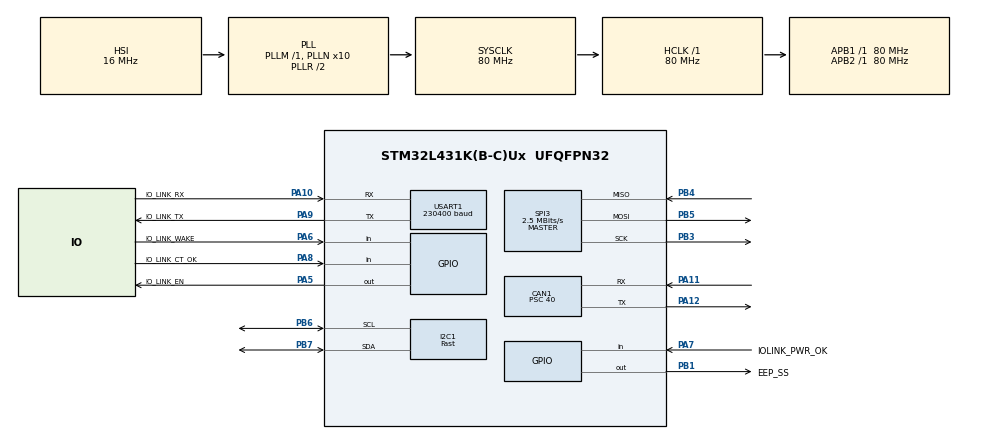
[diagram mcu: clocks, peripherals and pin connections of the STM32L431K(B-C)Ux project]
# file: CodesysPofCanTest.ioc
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CAN1.BS1=CAN_BS1_13TQ
CAN1.BS2=CAN_BS2_2TQ
CAN1.CalculateTimeQuantum=500.0
CAN1.Prescaler=40
CAN1.SJW=CAN_SJW_1TQ
I2C1.I2C_Speed_Mode=I2C_Fast
I2C1.Timing=0x00702991
Mcu.Family=STM32L4
Mcu.Name=STM32L431K(B-C)Ux
Mcu.Package=UFQFPN32
NVIC.CAN1_RX0_IRQn=true\:1\:0\:true\:false\:true\:true
NVIC.CAN1_RX1_IRQn=true\:1\:0\:true\:false\:true\:true
NVIC.CAN1_TX_IRQn=true\:1\:0\:true\:false\:true\:true
NVIC.PriorityGroup=NVIC_PRIORITYGROUP_4
NVIC.SPI3_IRQn=true\:0\:0\:false\:false\:true\:true
NVIC.USART1_IRQn=true\:0\:0\:false\:false\:true\:true
PA10.GPIO_Label=IO_LINK_RX
PA10.Mode=Asynchronous
PA10.Signal=USART1_RX
PA11.Mode=Master
PA11.Signal=CAN1_RX
PA12.Mode=Master
PA12.Signal=CAN1_TX
PA5.GPIO_Label=IO_LINK_EN
PA5.Signal=GPIO_Output
PA6.GPIO_Label=IO_LINK_WAKE
PA6.Signal=GPIO_Input
PA7.GPIO_Label=IOLINK_PWR_OK
PA7.Signal=GPIO_Input
PA8.GPIO_Label=IO_LINK_CT_OK
PA8.Signal=GPIO_Input
PA9.GPIO_Label=IO_LINK_TX
PA9.Mode=Asynchronous
PA9.Signal=USART1_TX
PB1.GPIO_Label=EEP_SS
PB1.Signal=GPIO_Output
PB3\ (JTDO-TRACESWO).Mode=Full_Duplex_Master
PB3\ (JTDO-TRACESWO).Signal=SPI3_SCK
PB4\ (NJTRST).Mode=Full_Duplex_Master
PB4\ (NJTRST).Signal=SPI3_MISO
PB5.Mode=Full_Duplex_Master
PB5.Signal=SPI3_MOSI
PB6.Mode=I2C
PB6.Signal=I2C1_SCL
PB7.Mode=I2C
PB7.Signal=I2C1_SDA
ProjectManager.HeapSize=0x200
ProjectManager.StackSize=0x400
ProjectManager.TargetToolchain=TrueSTUDIO
RCC.ADCFreq_Value=64000000
RCC.AHBFreq_Value=80000000
RCC.APB1Freq_Value=80000000
RCC.APB1TimFreq_Value=80000000
RCC.APB2Freq_Value=80000000
RCC.APB2TimFreq_Value=80000000
RCC.CortexFreq_Value=80000000
RCC.HCLKFreq_Value=80000000
RCC.HSE_VALUE=8000000
RCC.HSI48_VALUE=48000000
RCC.HSI_VALUE=16000000
RCC.LSE_VALUE=32768
RCC.MSI_VALUE=4000000
RCC.PLLN=10
RCC.PLLSourceVirtual=RCC_PLLSOURCE_HSI
RCC.SYSCLKFreq_VALUE=80000000
RCC.SYSCLKSource=RCC_SYSCLKSOURCE_PLLCLK
RCC.VCOOutputFreq_Value=160000000
SPI3.BaudRatePrescaler=SPI_BAUDRATEPRESCALER_32
SPI3.CalculateBaudRate=2.5 MBits/s
SPI3.DataSize=SPI_DATASIZE_8BIT
SPI3.Direction=SPI_DIRECTION_2LINES
SPI3.Mode=SPI_MODE_MASTER
SPI3.VirtualType=VM_MASTER
TIM6.Period=249
TIM6.Prescaler=319
USART1.BaudRate=230400
USART1.Parity=PARITY_EVEN
USART1.VirtualMode-Asynchronous=VM_ASYNC
USART1.WordLength=WORDLENGTH_9B
VP_TIM6_VS_ClockSourceINT.Mode=Enable_Timer
board=CodesysPofCanTest

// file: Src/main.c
/**
  ******************************************************************************
  * @file           : main.c
  * @brief          : Main program body
  ******************************************************************************
  ** This notice applies to any and all portions of this file
  * that are not between comment pairs USER CODE BEGIN and
  * USER CODE END. Other portions of this file, whether
  * inserted by the user or by software development tools
  * are owned by their respective copyright owners.
  *
  * COPYRIGHT(c) 2018 STMicroelectronics
  *
  * Redistribution and use in source and binary forms, with or without modification,
  * are permitted provided that the following conditions are met:
  *   1. Redistributions of source code must retain the above copyright notice,
  *      this list of conditions and the following disclaimer.
  *   2. Redistributions in binary form must reproduce the above copyright notice,
  *      this list of conditions and the following disclaimer in the documentation
  *      and/or other materials provided with the distribution.
  *   3. Neither the name of STMicroelectronics nor the names of its contributors
  *      may be used to endorse or promote products derived from this software
  *      without specific prior written permission.
  *
  * THIS SOFTWARE IS PROVIDED BY THE COPYRIGHT HOLDERS AND CONTRIBUTORS "AS IS"
  * AND ANY EXPRESS OR IMPLIED WARRANTIES, INCLUDING, BUT NOT LIMITED TO, THE
  * IMPLIED WARRANTIES OF MERCHANTABILITY AND FITNESS FOR A PARTICULAR PURPOSE ARE
  * DISCLAIMED. IN NO EVENT SHALL THE COPYRIGHT HOLDER OR CONTRIBUTORS BE LIABLE
  * FOR ANY DIRECT, INDIRECT, INCIDENTAL, SPECIAL, EXEMPLARY, OR CONSEQUENTIAL
  * DAMAGES (INCLUDING, BUT NOT LIMITED TO, PROCUREMENT OF SUBSTITUTE GOODS OR
  * SERVICES; LOSS OF USE, DATA, OR PROFITS; OR BUSINESS INTERRUPTION) HOWEVER
  * CAUSED AND ON ANY THEORY OF LIABILITY, WHETHER IN CONTRACT, STRICT LIABILITY,
  * OR TORT (INCLUDING NEGLIGENCE OR OTHERWISE) ARISING IN ANY WAY OUT OF THE USE
  * OF THIS SOFTWARE, EVEN IF ADVISED OF THE POSSIBILITY OF SUCH DAMAGE.
  *
  ******************************************************************************
  */
#include "main.h"
#include "stm32l4xx_hal.h"
#include "can.h"
#include "i2c.h"
#include "spi.h"
#include "tim.h"
#include "usart.h"
#include "gpio.h"

/* USER CODE BEGIN Includes */
#include "task.h"
/* USER CODE END Includes */

/* USER CODE BEGIN PV */
/* Private variables ---------------------------------------------------------*/

/* USER CODE END PV */

void SystemClock_Config(void);

/* USER CODE BEGIN PFP */
/* Private function prototypes -----------------------------------------------*/

/* USER CODE END PFP */

int main(void)
{

  /* MCU Configuration----------------------------------------------------------*/

  /* Reset of all peripherals, Initializes the Flash interface and the Systick. */
  HAL_Init();

  /* Configure the system clock */
  SystemClock_Config();

  /* Initialize all configured peripherals */
  MX_GPIO_Init();
  MX_CAN1_Init();
  MX_SPI3_Init();
  MX_TIM6_Init();
  MX_USART1_UART_Init();
  MX_I2C1_Init();
  /* USER CODE BEGIN 2 */
  task_coldStart();
  /* USER CODE END 2 */

  /* Infinite loop */
  while (1)
  {

  /* USER CODE BEGIN 3 */
	static uint32_t PreviousTicks = 0U;
	uint32_t CurrentTicks = HAL_GetTick();
	if((CurrentTicks - PreviousTicks) >= 1u)
	 {
			PreviousTicks = HAL_GetTick();
			task_oneMs();
	 }
  }
  /* USER CODE END 3 */

}

void SystemClock_Config(void)
{

  RCC_OscInitTypeDef RCC_OscInitStruct;
  RCC_ClkInitTypeDef RCC_ClkInitStruct;
  RCC_PeriphCLKInitTypeDef PeriphClkInit;

    /**Initializes the CPU, AHB and APB busses clocks
    */
  RCC_OscInitStruct.OscillatorType = RCC_OSCILLATORTYPE_HSI;
  RCC_OscInitStruct.HSIState = RCC_HSI_ON;
  RCC_OscInitStruct.HSICalibrationValue = RCC_HSICALIBRATION_DEFAULT;
  RCC_OscInitStruct.PLL.PLLState = RCC_PLL_ON;
  RCC_OscInitStruct.PLL.PLLSource = RCC_PLLSOURCE_HSI;
  RCC_OscInitStruct.PLL.PLLM = 1;
  RCC_OscInitStruct.PLL.PLLN = 10;
  RCC_OscInitStruct.PLL.PLLP = RCC_PLLP_DIV7;
  RCC_OscInitStruct.PLL.PLLQ = RCC_PLLQ_DIV2;
  RCC_OscInitStruct.PLL.PLLR = RCC_PLLR_DIV2;
  if (HAL_RCC_OscConfig(&RCC_OscInitStruct) != HAL_OK)
  {
    _Error_Handler(__FILE__, __LINE__);
  }

    /**Initializes the CPU, AHB and APB busses clocks
    */
  RCC_ClkInitStruct.ClockType = RCC_CLOCKTYPE_HCLK|RCC_CLOCKTYPE_SYSCLK
                              |RCC_CLOCKTYPE_PCLK1|RCC_CLOCKTYPE_PCLK2;
  RCC_ClkInitStruct.SYSCLKSource = RCC_SYSCLKSOURCE_PLLCLK;
  RCC_ClkInitStruct.AHBCLKDivider = RCC_SYSCLK_DIV1;
  RCC_ClkInitStruct.APB1CLKDivider = RCC_HCLK_DIV1;
  RCC_ClkInitStruct.APB2CLKDivider = RCC_HCLK_DIV1;

  if (HAL_RCC_ClockConfig(&RCC_ClkInitStruct, FLASH_LATENCY_4) != HAL_OK)
  {
    _Error_Handler(__FILE__, __LINE__);
  }

  PeriphClkInit.PeriphClockSelection = RCC_PERIPHCLK_USART1|RCC_PERIPHCLK_I2C1;
  PeriphClkInit.Usart1ClockSelection = RCC_USART1CLKSOURCE_PCLK2;
  PeriphClkInit.I2c1ClockSelection = RCC_I2C1CLKSOURCE_PCLK1;
  if (HAL_RCCEx_PeriphCLKConfig(&PeriphClkInit) != HAL_OK)
  {
    _Error_Handler(__FILE__, __LINE__);
  }

    /**Configure the main internal regulator output voltage
    */
  if (HAL_PWREx_ControlVoltageScaling(PWR_REGULATOR_VOLTAGE_SCALE1) != HAL_OK)
  {
    _Error_Handler(__FILE__, __LINE__);
  }

    /**Configure the Systick interrupt time
    */
  HAL_SYSTICK_Config(HAL_RCC_GetHCLKFreq()/1000);

    /**Configure the Systick
    */
  HAL_SYSTICK_CLKSourceConfig(SYSTICK_CLKSOURCE_HCLK);

  /* SysTick_IRQn interrupt configuration */
  HAL_NVIC_SetPriority(SysTick_IRQn, 0, 0);
}

void _Error_Handler(char *file, int line)
{
  while(1)
  {
  }
}

/************************ (C) COPYRIGHT STMicroelectronics *****END OF FILE****/
